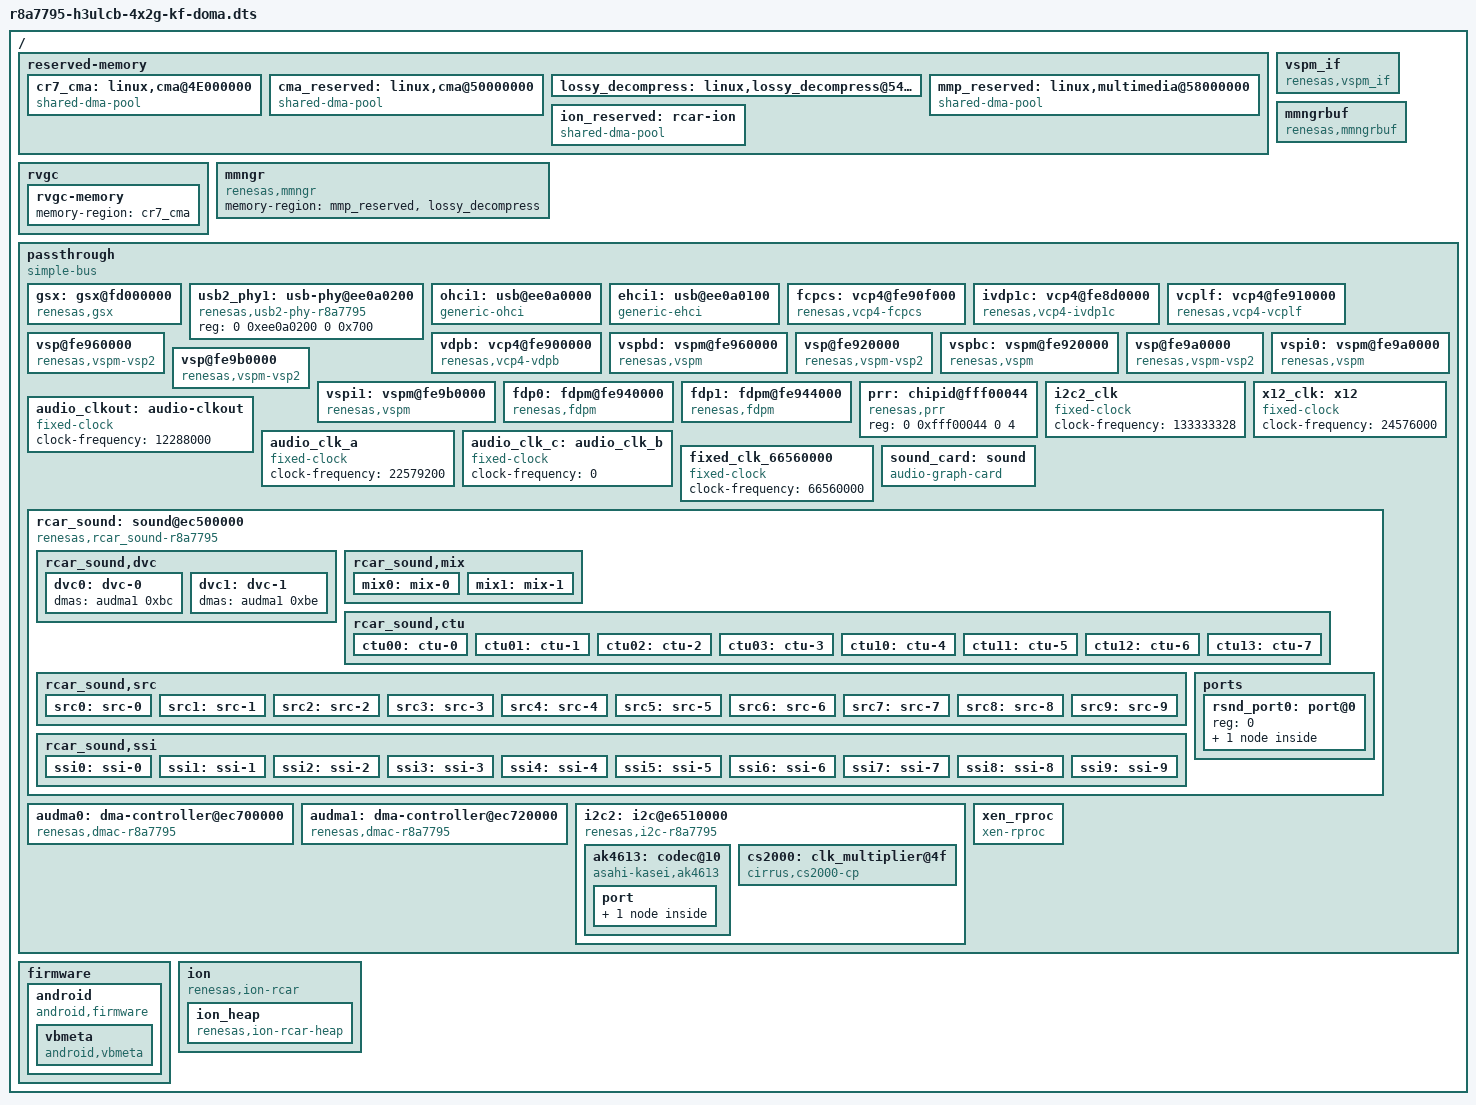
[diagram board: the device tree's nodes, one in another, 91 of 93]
/dts-v1/;

#include <dt-bindings/interrupt-controller/arm-gic.h>

/ {

	#address-cells = <2>;
	#size-cells = <2>;

	reserved-memory {
		#address-cells = <2>;
		#size-cells = <2>;
		ranges;

		/* CR7 vrings and graphics buffers */
		cr7_cma: linux,cma@4E000000 {
			compatible = "shared-dma-pool";
			reg = <0x0 0x4E000000 0x0 0x2000000>;
			reusable;
		};

		/* global autoconfigured region for contiguous allocations */
		cma_reserved: linux,cma@50000000 {
			compatible = "shared-dma-pool";
			reusable;
			reg = <0x00000000 0x50000000 0x0 0x04000000>; /* 64Mb */
			linux,cma-default;
		};

		/* device specific region for Lossy Decompression */
		lossy_decompress: linux,lossy_decompress@54000000 {
			no-map;
			reg = <0x00000000 0x54000000 0x0 0x03000000>;
		};

		/* device specific region for contiguous allocations */
		mmp_reserved: linux,multimedia@58000000 {
			compatible = "shared-dma-pool";
			reusable;
			reg = <0x00000000 0x58000000 0x0 0x10000000>; /* 256Mb */
		};

		ion_reserved: rcar-ion {
			compatible = "shared-dma-pool";
			reusable;
			reg = <0x00000000 0x68000000 0x0 0x20000000>; /* 512Mb */
		};
	};

	rvgc {
		nr-displays = <0x1>;
		display-mappings = <0x1>;
		display-layer = <0x3>;

		dma-ranges = <0x0 0x0 0x0 0x0 0x1 0x0>;
		rvgc-memory {
			memory-region = <&cr7_cma>;
		};
	};

	vspm_if {
		compatible = "renesas,vspm_if";
	};

	mmngr {
		compatible = "renesas,mmngr";
		memory-region = <&mmp_reserved>, <&lossy_decompress>;
	};

	mmngrbuf {
		compatible = "renesas,mmngrbuf";
	};

	passthrough {
		compatible = "simple-bus";
		ranges;
		#address-cells = <2>;
		#size-cells = <2>;

		gsx: gsx@fd000000 {
			compatible = "renesas,gsx";
			reg = <0 0xfd000000 0 0x3ffff>;
			interrupts = <GIC_SPI 119 IRQ_TYPE_LEVEL_HIGH>;
			/*clocks = <&cpg CPG_MOD 112>;*/
			/*power-domains = <&sysc R8A7795_PD_3DG_E>;*/
		};

		usb2_phy1: usb-phy@ee0a0200 {
			compatible = "renesas,usb2-phy-r8a7795",
				     "renesas,rcar-gen3-usb2-phy";
			reg = <0 0xee0a0200 0 0x700>;
			#phy-cells = <0>;
			/* clocks = <&cpg CPG_MOD 702>; */
			/* power-domains = <&sysc R8A7795_PD_ALWAYS_ON>; */
			/* resets = <&cpg 702>; */
			/* pinctrl-0 = <&usb1_pins>; */
			/* pinctrl-names = "default"; */
		};
		ohci1: usb@ee0a0000 {
			compatible = "generic-ohci";
			reg = <0 0xee0a0000 0 0x100>;
			interrupts = <GIC_SPI 112 IRQ_TYPE_LEVEL_HIGH>;
			phys = <&usb2_phy1 1>;
			phy-names = "usb";
			/* clocks = <&cpg CPG_MOD 702>; */
			/* power-domains = <&sysc R8A7795_PD_ALWAYS_ON>; */
			/* resets = <&cpg 702>; */
		};
		ehci1: usb@ee0a0100 {
			compatible = "generic-ehci";
			reg = <0 0xee0a0100 0 0x100>;
			interrupts = <GIC_SPI 112 IRQ_TYPE_LEVEL_HIGH>;
			companion = <&ohci1>;
			phys = <&usb2_phy1 2>;
			phy-names = "usb";
			/* clocks = <&cpg CPG_MOD 702>; */
			/* power-domains = <&sysc R8A7795_PD_ALWAYS_ON>; */
			/* resets = <&cpg 702>; */
		};

		fcpcs: vcp4@fe90f000 {
			compatible = "renesas,vcp4-fcpcs";
			reg = <0 0xfe90f000 0 0x200>;
			/*clocks = <&cpg CPG_MOD 619>;*/
			/*power-domains = <&sysc R8A7795_PD_A3VC>;*/
			/*resets = <&cpg 619>;*/
			renesas,#ch = <0>;
		};

		ivdp1c: vcp4@fe8d0000 {
			compatible = "renesas,vcp4-ivdp1c";
			reg = <0 0xfe8d0000 0 0x200>, <0 0xfe8d0200 0 0x200>;
			interrupts = <GIC_SPI 380 IRQ_TYPE_LEVEL_HIGH>,
			     <GIC_SPI 381 IRQ_TYPE_LEVEL_HIGH>,
			     <GIC_SPI 223 IRQ_TYPE_LEVEL_HIGH>;
			/*clocks = <&cpg CPG_MOD 130>;*/
			/*power-domains = <&sysc R8A7795_PD_A2VC1>;*/
			/*resets = <&cpg 130>;*/
			renesas,#ch = <2>;
			renesas,#fcp_ch = <0>;
		};

		vcplf: vcp4@fe910000 {
			compatible = "renesas,vcp4-vcplf";
			reg = <0 0xfe910000 0 0x200>, <0 0xfe910200 0 0x200>;
			interrupts = <GIC_SPI 260 IRQ_TYPE_LEVEL_HIGH>,
				     <GIC_SPI 261 IRQ_TYPE_LEVEL_HIGH>;
			/*clocks = <&cpg CPG_MOD 130>;*/
			/*power-domains = <&sysc R8A7795_PD_A2VC1>;*/
			/*resets = <&cpg 130>;*/
			renesas,#ch = <0>;
			renesas,#fcp_ch = <0>;
		};

		vdpb: vcp4@fe900000 {
			compatible = "renesas,vcp4-vdpb";
			reg = <0 0xfe900000 0 0x200>, <0 0xfe900200 0 0x200>;
			interrupts = <GIC_SPI 240 IRQ_TYPE_LEVEL_HIGH>,
				     <GIC_SPI 241 IRQ_TYPE_LEVEL_HIGH>;
			/*clocks = <&cpg CPG_MOD 131>;*/
			/*power-domains = <&sysc R8A7795_PD_A2VC1>;*/
			/*resets = <&cpg 131>;*/
			renesas,#ch = <1>;
			renesas,#fcp_ch = <0>;
		};

		vsp@fe960000 {
			compatible = "renesas,vspm-vsp2";
			reg = <0 0xfe960000 0 0x8000>;
			renesas,has-bru;
			renesas,#rpf = <5>;
			renesas,#uds = <0>;
			renesas,#wpf = <1>;
		};

		vspbd: vspm@fe960000 {
			compatible = "renesas,vspm";
			reg = <0 0xfe960000 0 0x8000>, <0 0xfe96f000 0 0x200>;
			interrupts = <GIC_SPI 266 IRQ_TYPE_LEVEL_HIGH>;
			/*clocks = <&cpg CPG_MOD 626>, <&cpg CPG_MOD 607>;*/
			/*clock-names = "vsp", "fcp";*/
			renesas,#ch = <3>;
			renesas,#rpf = <31>;
			renesas,#rpf_clut = <6>;
			renesas,#wpf_rot = <0>;
			renesas,has-bru;
			renesas,#read_outstanding = <0>;
			renesas,#start_reservation = <2>;
			renesas,#burst_access = <0>;
			/*power-domains = <&sysc R8A7795_PD_A3VP>;*/
			/*resets = <&cpg 626>, <&cpg 607>;*/
			/*reset-names = "vsp", "fcp";*/
			/*status = "disabled";*/
		};

		vsp@fe920000 {
			compatible = "renesas,vspm-vsp2";
			reg = <0 0xfe920000 0 0x8000>;
			renesas,has-bru;
			renesas,has-lut;
			renesas,has-clu;
			renesas,has-hgo;
			renesas,#rpf = <5>;
			renesas,#uds = <0>;
			renesas,#wpf = <1>;
		};

		vspbc: vspm@fe920000 {
			compatible = "renesas,vspm";
			reg = <0 0xfe920000 0 0x8000>, <0 0xfe92f000 0 0x200>;
			interrupts = <GIC_SPI 465 IRQ_TYPE_LEVEL_HIGH>;
			/*clocks = <&cpg CPG_MOD 624>, <&cpg CPG_MOD 606>;*/
			/*clock-names = "vsp", "fcp";*/
			renesas,#ch = <4>;
			renesas,#rpf = <31>;
			renesas,#rpf_clut = <6>;
			renesas,#wpf_rot = <0>;
			renesas,has-lut;
			renesas,has-clu;
			renesas,has-hgo;
			renesas,has-bru;
			renesas,#read_outstanding = <0>;
			renesas,#start_reservation = <2>;
			renesas,#burst_access = <1>;
			/*power-domains = <&sysc R8A7795_PD_A3VP>;*/
			/*resets = <&cpg 624>, <&cpg 606>;*/
			/*reset-names = "vsp", "fcp";*/
			/*status = "disabled";*/
		};

		vsp@fe9a0000 {
			compatible = "renesas,vspm-vsp2";
			reg = <0 0xfe9a0000 0 0x8000>;
			renesas,has-lut;
			renesas,has-clu;
			renesas,has-hgo;
			renesas,has-hgt;
			renesas,#rpf = <1>;
			renesas,#uds = <1>;
			renesas,#wpf = <1>;
		};

		vspi0: vspm@fe9a0000 {
			compatible = "renesas,vspm";
			reg = <0 0xfe9a0000 0 0x8000>, <0 0xfe9af000 0 0x200>;
			interrupts = <GIC_SPI 444 IRQ_TYPE_LEVEL_HIGH>;
			/*clocks = <&cpg CPG_MOD 631>, <&cpg CPG_MOD 611>;*/
			/*clock-names = "vsp", "fcp";*/
			renesas,#ch = <0>;
			renesas,#rpf = <1>;
			renesas,#rpf_clut = <1>;
			renesas,#wpf_rot = <1>;
			renesas,has-sru;
			renesas,has-uds;
			renesas,has-lut;
			renesas,has-clu;
			renesas,has-hst;
			renesas,has-hsi;
			renesas,has-hgo;
			renesas,has-hgt;
			renesas,has-shp;
			renesas,#read_outstanding = <2>;
			renesas,#start_reservation = <2>;
			/*power-domains = <&sysc R8A7795_PD_A3VP>;*/
			/*resets = <&cpg 631>, <&cpg 611>;*/
			/*reset-names = "vsp", "fcp";*/
			/*status = "disabled";*/
		};

		vsp@fe9b0000 {
			compatible = "renesas,vspm-vsp2";
			reg = <0 0xfe9b0000 0 0x8000>;
			renesas,has-lut;
			renesas,has-clu;
			renesas,has-hgo;
			renesas,has-hgt;
			renesas,#rpf = <1>;
			renesas,#uds = <1>;
			renesas,#wpf = <1>;
		};

		vspi1: vspm@fe9b0000 {
			compatible = "renesas,vspm";
			reg = <0 0xfe9b0000 0 0x8000>, <0 0xfe9bf000 0 0x200>;
			interrupts = <GIC_SPI 445 IRQ_TYPE_LEVEL_HIGH>;
			/*clocks = <&cpg CPG_MOD 630>, <&cpg CPG_MOD 610>;*/
			/*clock-names = "vsp", "fcp";*/
			renesas,#ch = <1>;
			renesas,#rpf = <1>;
			renesas,#rpf_clut = <1>;
			renesas,#wpf_rot = <1>;
			renesas,has-sru;
			renesas,has-uds;
			renesas,has-lut;
			renesas,has-clu;
			renesas,has-hst;
			renesas,has-hsi;
			renesas,has-hgo;
			renesas,has-hgt;
			renesas,has-shp;
			renesas,#read_outstanding = <2>;
			renesas,#start_reservation = <2>;
			/*power-domains = <&sysc R8A7795_PD_A3VP>;*/
			/*resets = <&cpg 630>, <&cpg 610>;*/
			/*reset-names = "vsp", "fcp";*/
			/*status = "disabled";*/
		};

		fdp0: fdpm@fe940000 {
			compatible = "renesas,fdpm";
			reg = <0 0xfe940000 0 0x2400>, <0 0xfe950000 0 0x200>;
			interrupts = <GIC_SPI 262 IRQ_TYPE_LEVEL_HIGH>;
			/*clocks = <&cpg CPG_MOD 119>, <&cpg CPG_MOD 615>;*/
			/*clock-names = "fdp", "fcp";*/
			/*power-domains = <&sysc R8A7795_PD_A3VP>;*/
			/*resets = <&cpg 119>, <&cpg 615>;*/
			/*reset-names = "fdp", "fcp";*/
			renesas,#ch = <0>;
		};

		fdp1: fdpm@fe944000 {
			compatible = "renesas,fdpm";
			reg = <0 0xfe944000 0 0x2400>, <0 0xfe951000 0 0x200>;
			interrupts = <GIC_SPI 263 IRQ_TYPE_LEVEL_HIGH>;
			/*clocks = <&cpg CPG_MOD 118>, <&cpg CPG_MOD 614>;*/
			/*clock-names = "fdp", "fcp";*/
			/*power-domains = <&sysc R8A7795_PD_A3VP>;*/
			/*resets = <&cpg 118>, <&cpg 614>;*/
			/*reset-names = "fdp", "fcp";*/
			renesas,#ch = <1>;
		};

		prr: chipid@fff00044 {
			compatible = "renesas,prr";
			reg = <0 0xfff00044 0 4>;
		};

		i2c2_clk: i2c2_clk {
			compatible = "fixed-clock";
			clock-frequency = <133333328>;
			#clock-cells = <0>;
		};

		audio_clkout: audio-clkout {
			/*
			 * This is same as <&rcar_sound 0>
			 * but needed to avoid cs2000/rcar_sound probe dead-lock
			 */
			compatible = "fixed-clock";
			#clock-cells = <0>;
			clock-frequency = <12288000>;
		};
		x12_clk: x12 {
			compatible = "fixed-clock";
			#clock-cells = <0>;
			clock-frequency = <24576000>;
		};
		audio_clk_a: audio_clk_a {
			compatible = "fixed-clock";
			#clock-cells = <0>;
			clock-frequency = <22579200>;
		};
		audio_clk_c: audio_clk_b {
			compatible = "fixed-clock";
			#clock-cells = <0>;
			clock-frequency = <0>;
		};
		fixed_clk_66560000: fixed_clk_66560000 {
			compatible = "fixed-clock";
			#clock-cells = <0>;
			clock-frequency = <66560000>;
		};
		sound_card: sound {
			compatible = "audio-graph-card";
			label = "rcar-sound";
			dais = <&rsnd_port0>;
		};
		rcar_sound: sound@ec500000 {
			/*
			 * #sound-dai-cells is required
			 *
			 * Single DAI : #sound-dai-cells = <0>;	<&rcar_sound>;
			 * Multi  DAI : #sound-dai-cells = <1>;	<&rcar_sound N>;
			 */
			/*
			 * #clock-cells is required for audio_clkout0/1/2/3
			 *
			 * clkout	: #clock-cells = <0>;	<&rcar_sound>;
			 * clkout0/1/2/3: #clock-cells = <1>;	<&rcar_sound N>;
			 */
			compatible =  "renesas,rcar_sound-r8a7795", "renesas,rcar_sound-gen3";
			reg =	<0 0xec500000 0 0x1000>, /* SCU */
				<0 0xec5a0000 0 0x100>,  /* ADG */
				<0 0xec540000 0 0x1000>, /* SSIU */
				<0 0xec541000 0 0x280>,  /* SSI */
				<0 0xec760000 0 0x200>,  /* Audio DMAC peri peri*/
				<0 0xec000000 0 0x1000>,
				<0 0xec008000 0 0x1000>;
			reg-names = "scu", "adg", "ssiu", "ssi", "audmapp";

			clocks =
				 /* "ssi-all" */
				 <&fixed_clk_66560000>,
				 /* "ssi.9", "ssi.8" */
				 <&fixed_clk_66560000>, <&fixed_clk_66560000>,
				 /* "ssi.7", "ssi.6" */
				 <&fixed_clk_66560000>, <&fixed_clk_66560000>,
				 /* "ssi.5", "ssi.4" */
				 <&fixed_clk_66560000>, <&fixed_clk_66560000>,
				 /* "ssi.3", "ssi.2" */
				 <&fixed_clk_66560000>, <&fixed_clk_66560000>,
				 /* "ssi.1", "ssi.0" */
				 <&fixed_clk_66560000>, <&fixed_clk_66560000>,
				 /* "src.9", "src.8" */
				 <&fixed_clk_66560000>, <&fixed_clk_66560000>,
				 /* "src.7", "src.6" */
				 <&fixed_clk_66560000>, <&fixed_clk_66560000>,
				 /* "src.5", "src.4" */
				 <&fixed_clk_66560000>, <&fixed_clk_66560000>,
				 /* "src.3", "src.2" */
				 <&fixed_clk_66560000>, <&fixed_clk_66560000>,
				 /* "src.1", "src.0" */
				 <&fixed_clk_66560000>, <&fixed_clk_66560000>,
				 /* "mix.1", "mix.0" */
				 <&fixed_clk_66560000>, <&fixed_clk_66560000>,
				 /* "ctu.1", "ctu.0" */
				 <&fixed_clk_66560000>, <&fixed_clk_66560000>,
				 /* "dvc.0", "dvc.1" */
				 <&fixed_clk_66560000>, <&fixed_clk_66560000>,
				 /* "clk_a", "clk_b" */
				 <&audio_clk_a>, <&cs2000>,
				 /* "clk_c", "clk_i" */
				 <&audio_clk_c>, <&i2c2_clk>;

			clock-names = "ssi-all",
				      "ssi.9", "ssi.8",
				      "ssi.7", "ssi.6",
				      "ssi.5", "ssi.4",
				      "ssi.3", "ssi.2",
				      "ssi.1", "ssi.0",
				      "src.9", "src.8",
				      "src.7", "src.6",
				      "src.5", "src.4",
				      "src.3", "src.2",
				      "src.1", "src.0",
				      "mix.1", "mix.0",
				      "ctu.1", "ctu.0",
				      "dvc.0", "dvc.1",
				      "clk_a", "clk_b",
				      "clk_c", "clk_i";

			/*
			pinctrl-0 = <&sound_pins &sound_clk_pins>;
			pinctrl-names = "default";
			*/

			/* Single DAI */
			#sound-dai-cells = <0>;

			/* audio_clkout0/1/2/3 */
			#clock-cells = <1>;
			clock-frequency = <12288000 11289600>;

			status = "okay";

			rcar_sound,dvc {
				dvc0: dvc-0 {
					dmas = <&audma1 0xbc>;
					dma-names = "tx";
				};
				dvc1: dvc-1 {
					dmas = <&audma1 0xbe>;
					dma-names = "tx";
				};
			};

			rcar_sound,mix {
				mix0: mix-0 { };
				mix1: mix-1 { };
			};

			rcar_sound,ctu {
				ctu00: ctu-0 { };
				ctu01: ctu-1 { };
				ctu02: ctu-2 { };
				ctu03: ctu-3 { };
				ctu10: ctu-4 { };
				ctu11: ctu-5 { };
				ctu12: ctu-6 { };
				ctu13: ctu-7 { };
			};

			rcar_sound,src {
				src0: src-0 {
					interrupts = <GIC_SPI 352 IRQ_TYPE_LEVEL_HIGH>;
					dmas = <&audma0 0x85>, <&audma1 0x9a>;
					dma-names = "rx", "tx";
				};
				src1: src-1 {
					interrupts = <GIC_SPI 353 IRQ_TYPE_LEVEL_HIGH>;
					dmas = <&audma0 0x87>, <&audma1 0x9c>;
					dma-names = "rx", "tx";
				};
				src2: src-2 {
					interrupts = <GIC_SPI 354 IRQ_TYPE_LEVEL_HIGH>;
					dmas = <&audma0 0x89>, <&audma1 0x9e>;
					dma-names = "rx", "tx";
				};
				src3: src-3 {
					interrupts = <GIC_SPI 355 IRQ_TYPE_LEVEL_HIGH>;
					dmas = <&audma0 0x8b>, <&audma1 0xa0>;
					dma-names = "rx", "tx";
				};
				src4: src-4 {
					interrupts = <GIC_SPI 356 IRQ_TYPE_LEVEL_HIGH>;
					dmas = <&audma0 0x8d>, <&audma1 0xb0>;
					dma-names = "rx", "tx";
				};
				src5: src-5 {
					interrupts = <GIC_SPI 357 IRQ_TYPE_LEVEL_HIGH>;
					dmas = <&audma0 0x8f>, <&audma1 0xb2>;
					dma-names = "rx", "tx";
				};
				src6: src-6 {
					interrupts = <GIC_SPI 358 IRQ_TYPE_LEVEL_HIGH>;
					dmas = <&audma0 0x91>, <&audma1 0xb4>;
					dma-names = "rx", "tx";
				};
				src7: src-7 {
					interrupts = <GIC_SPI 359 IRQ_TYPE_LEVEL_HIGH>;
					dmas = <&audma0 0x93>, <&audma1 0xb6>;
					dma-names = "rx", "tx";
				};
				src8: src-8 {
					interrupts = <GIC_SPI 360 IRQ_TYPE_LEVEL_HIGH>;
					dmas = <&audma0 0x95>, <&audma1 0xb8>;
					dma-names = "rx", "tx";
				};
				src9: src-9 {
					interrupts = <GIC_SPI 361 IRQ_TYPE_LEVEL_HIGH>;
					dmas = <&audma0 0x97>, <&audma1 0xba>;
					dma-names = "rx", "tx";
				};
			};

			rcar_sound,ssi {
				ssi0: ssi-0 {
					interrupts = <GIC_SPI 370 IRQ_TYPE_LEVEL_HIGH>;
					dmas = <&audma0 0x01>, <&audma1 0x02>, <&audma0 0x15>, <&audma1 0x16>;
					dma-names = "rx", "tx", "rxu", "txu";
				};
				ssi1: ssi-1 {
					interrupts = <GIC_SPI 371 IRQ_TYPE_LEVEL_HIGH>;
					dmas = <&audma0 0x03>, <&audma1 0x04>, <&audma0 0x49>, <&audma1 0x4a>;
					dma-names = "rx", "tx", "rxu", "txu";
				};
				ssi2: ssi-2 {
					interrupts = <GIC_SPI 372 IRQ_TYPE_LEVEL_HIGH>;
					dmas = <&audma0 0x05>, <&audma1 0x06>, <&audma0 0x63>, <&audma1 0x64>;
					dma-names = "rx", "tx", "rxu", "txu";
				};
				ssi3: ssi-3 {
					interrupts = <GIC_SPI 373 IRQ_TYPE_LEVEL_HIGH>;
					dmas = <&audma0 0x07>, <&audma1 0x08>, <&audma0 0x6f>, <&audma1 0x70>;
					dma-names = "rx", "tx", "rxu", "txu";
				};
				ssi4: ssi-4 {
					interrupts = <GIC_SPI 374 IRQ_TYPE_LEVEL_HIGH>;
					dmas = <&audma0 0x09>, <&audma1 0x0a>, <&audma0 0x71>, <&audma1 0x72>;
					dma-names = "rx", "tx", "rxu", "txu";
				};
				ssi5: ssi-5 {
					interrupts = <GIC_SPI 375 IRQ_TYPE_LEVEL_HIGH>;
					dmas = <&audma0 0x0b>, <&audma1 0x0c>, <&audma0 0x73>, <&audma1 0x74>;
					dma-names = "rx", "tx", "rxu", "txu";
				};
				ssi6: ssi-6 {
					interrupts = <GIC_SPI 376 IRQ_TYPE_LEVEL_HIGH>;
					dmas = <&audma0 0x0d>, <&audma1 0x0e>, <&audma0 0x75>, <&audma1 0x76>;
					dma-names = "rx", "tx", "rxu", "txu";
				};
				ssi7: ssi-7 {
					interrupts = <GIC_SPI 377 IRQ_TYPE_LEVEL_HIGH>;
					dmas = <&audma0 0x0f>, <&audma1 0x10>, <&audma0 0x79>, <&audma1 0x7a>;
					dma-names = "rx", "tx", "rxu", "txu";
				};
				ssi8: ssi-8 {
					interrupts = <GIC_SPI 378 IRQ_TYPE_LEVEL_HIGH>;
					dmas = <&audma0 0x11>, <&audma1 0x12>, <&audma0 0x7b>, <&audma1 0x7c>;
					dma-names = "rx", "tx", "rxu", "txu";
				};
				ssi9: ssi-9 {
					interrupts = <GIC_SPI 379 IRQ_TYPE_LEVEL_HIGH>;
					dmas = <&audma0 0x13>, <&audma1 0x14>, <&audma0 0x7d>, <&audma1 0x7e>;
					dma-names = "rx", "tx", "rxu", "txu";
				};
			};

			ports {
				#address-cells = <1>;
				#size-cells = <0>;
				rsnd_port0: port@0 {
					reg = <0>;
					rsnd_endpoint0: endpoint {
						remote-endpoint = <&ak4613_endpoint>;

						dai-format = "left_j";
						bitclock-master = <&rsnd_endpoint0>;
						frame-master = <&rsnd_endpoint0>;

						playback = <&ssi0 &src0 &dvc0>;
						capture  = <&ssi1 &src1 &dvc1>;
					};
				};
			};
		};

		audma0: dma-controller@ec700000 {
			compatible = "renesas,dmac-r8a7795",
				     "renesas,rcar-dmac";
			reg = <0 0xec700000 0 0x10000>;
			interrupts = <GIC_SPI 350 IRQ_TYPE_LEVEL_HIGH
				      GIC_SPI 320 IRQ_TYPE_LEVEL_HIGH
				      GIC_SPI 321 IRQ_TYPE_LEVEL_HIGH
				      GIC_SPI 322 IRQ_TYPE_LEVEL_HIGH
				      GIC_SPI 323 IRQ_TYPE_LEVEL_HIGH
				      GIC_SPI 324 IRQ_TYPE_LEVEL_HIGH
				      GIC_SPI 325 IRQ_TYPE_LEVEL_HIGH
				      GIC_SPI 326 IRQ_TYPE_LEVEL_HIGH
				      GIC_SPI 327 IRQ_TYPE_LEVEL_HIGH
				      GIC_SPI 328 IRQ_TYPE_LEVEL_HIGH
				      GIC_SPI 329 IRQ_TYPE_LEVEL_HIGH
				      GIC_SPI 330 IRQ_TYPE_LEVEL_HIGH
				      GIC_SPI 331 IRQ_TYPE_LEVEL_HIGH
				      GIC_SPI 332 IRQ_TYPE_LEVEL_HIGH
				      GIC_SPI 333 IRQ_TYPE_LEVEL_HIGH
				      GIC_SPI 334 IRQ_TYPE_LEVEL_HIGH
				      GIC_SPI 335 IRQ_TYPE_LEVEL_HIGH>;
			interrupt-names = "error",
					"ch0", "ch1", "ch2", "ch3",
					"ch4", "ch5", "ch6", "ch7",
					"ch8", "ch9", "ch10", "ch11",
					"ch12", "ch13", "ch14", "ch15";
			#dma-cells = <1>;
			dma-channels = <16>;
		};

		audma1: dma-controller@ec720000 {
			compatible = "renesas,dmac-r8a7795",
				     "renesas,rcar-dmac";
			reg = <0 0xec720000 0 0x10000>;
			interrupts = <GIC_SPI 351 IRQ_TYPE_LEVEL_HIGH
				      GIC_SPI 336 IRQ_TYPE_LEVEL_HIGH
				      GIC_SPI 337 IRQ_TYPE_LEVEL_HIGH
				      GIC_SPI 338 IRQ_TYPE_LEVEL_HIGH
				      GIC_SPI 339 IRQ_TYPE_LEVEL_HIGH
				      GIC_SPI 340 IRQ_TYPE_LEVEL_HIGH
				      GIC_SPI 341 IRQ_TYPE_LEVEL_HIGH
				      GIC_SPI 342 IRQ_TYPE_LEVEL_HIGH
				      GIC_SPI 343 IRQ_TYPE_LEVEL_HIGH
				      GIC_SPI 344 IRQ_TYPE_LEVEL_HIGH
				      GIC_SPI 345 IRQ_TYPE_LEVEL_HIGH
				      GIC_SPI 346 IRQ_TYPE_LEVEL_HIGH
				      GIC_SPI 347 IRQ_TYPE_LEVEL_HIGH
				      GIC_SPI 348 IRQ_TYPE_LEVEL_HIGH
				      GIC_SPI 349 IRQ_TYPE_LEVEL_HIGH
				      GIC_SPI 382 IRQ_TYPE_LEVEL_HIGH
				      GIC_SPI 383 IRQ_TYPE_LEVEL_HIGH>;
			interrupt-names = "error",
					"ch0", "ch1", "ch2", "ch3",
					"ch4", "ch5", "ch6", "ch7",
					"ch8", "ch9", "ch10", "ch11",
					"ch12", "ch13", "ch14", "ch15";
			#dma-cells = <1>;
			dma-channels = <16>;
		};

		i2c2: i2c@e6510000 {
			#address-cells = <1>;
			#size-cells = <0>;
			compatible = "renesas,i2c-r8a7795",
				     "renesas,rcar-gen3-i2c";
			reg = <0 0xe6510000 0 0x40>;
			interrupts = <GIC_SPI 286 IRQ_TYPE_LEVEL_HIGH>;
			/*
			clocks = <&cpg CPG_MOD 929>;
			power-domains = <&sysc R8A7795_PD_ALWAYS_ON>;
			resets = <&cpg 929>;
			*/
			clocks = <&i2c2_clk>;

			/*
			 * FIXME: Force dmac1/dmac2 to be not used as this
			 * DMA controller cannot be shared.
			 */
			/*
			dmas = <&dmac1 0x95>, <&dmac1 0x94>,
			       <&dmac2 0x95>, <&dmac2 0x94>;
			dma-names = "tx", "rx", "tx", "rx";
			*/
			i2c-scl-internal-delay-ns = <6>;

			/*
			pinctrl-0 = <&i2c2_pins>;
			pinctrl-names = "default";
			*/

			status = "okay";

			clock-frequency = <100000>;

			ak4613: codec@10 {
				compatible = "asahi-kasei,ak4613";
				#sound-dai-cells = <0>;
				reg = <0x10>;
				clocks = <&rcar_sound 3>;

				asahi-kasei,in1-single-end;
				asahi-kasei,in2-single-end;
				asahi-kasei,out1-single-end;
				asahi-kasei,out2-single-end;
				asahi-kasei,out3-single-end;
				asahi-kasei,out4-single-end;
				asahi-kasei,out5-single-end;
				asahi-kasei,out6-single-end;

				port {
					ak4613_endpoint: endpoint {
						remote-endpoint = <&rsnd_endpoint0>;
					};
				};
			};

			cs2000: clk_multiplier@4f {
				#clock-cells = <0>;
				compatible = "cirrus,cs2000-cp";
				reg = <0x4f>;
				clocks = <&audio_clkout>, <&x12_clk>;
				clock-names = "clk_in", "ref_clk";
				assigned-clocks = <&cs2000>;
				assigned-clock-rates = <24576000>; /* 1/1 divide */
			};
		};

		xen_rproc {
			dma-ranges = <0x0 0x0 0x0 0x0 0x1 0x0>;
			memory-region = <&cr7_cma>;
			compatible = "xen-rproc";
			interrupts = <0x00 233 0x04>;
			interrupt-names = "xen-rproc";
 		};
	};

	firmware {
		android {
			compatible = "android,firmware";

			vbmeta {
                                compatible = "android,vbmeta";
                                /* partitions witch can be mount in the first stage */
                                parts = "vbmeta,boot";
                                by_name_prefix="/dev/block/by-name";
                        };
		};
	};

	ion {
		compatible = "renesas,ion-rcar";

		ion_heap {
			compatible = "renesas,ion-rcar-heap";
			memory-region = <&ion_reserved>;
			heap-name = "rcar-ion";
		};
	};
};
